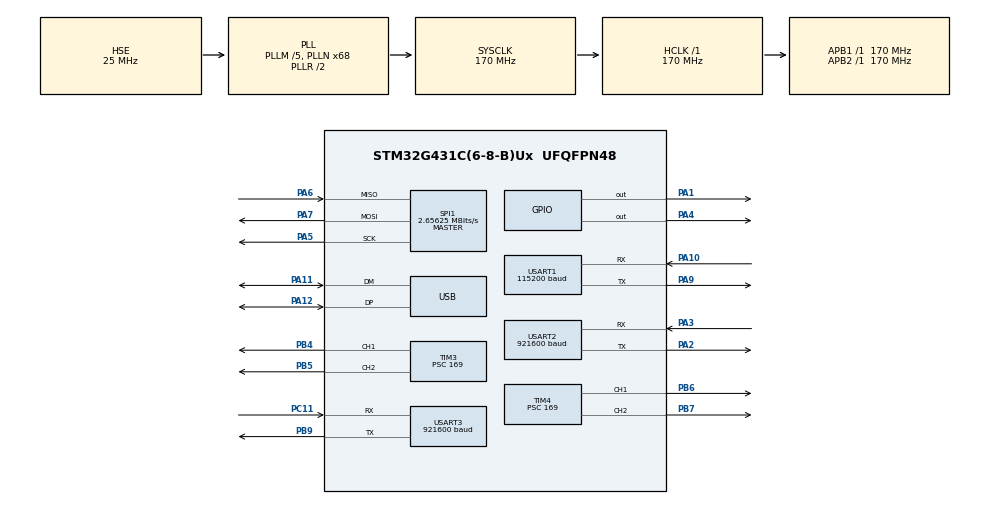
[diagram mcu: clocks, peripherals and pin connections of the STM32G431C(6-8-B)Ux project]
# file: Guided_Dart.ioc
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Dma.Request0=USART2_RX
Dma.Request1=USART2_TX
Dma.Request2=USART1_RX
Dma.Request3=USART1_TX
Dma.Request4=USART3_RX
Dma.Request5=USART3_TX
Dma.USART1_RX.2.Direction=DMA_PERIPH_TO_MEMORY
Dma.USART1_RX.2.EventEnable=DISABLE
Dma.USART1_RX.2.Instance=DMA1_Channel3
Dma.USART1_RX.2.MemDataAlignment=DMA_MDATAALIGN_BYTE
Dma.USART1_RX.2.MemInc=DMA_MINC_ENABLE
Dma.USART1_RX.2.Mode=DMA_NORMAL
Dma.USART1_RX.2.PeriphDataAlignment=DMA_PDATAALIGN_BYTE
Dma.USART1_RX.2.PeriphInc=DMA_PINC_DISABLE
Dma.USART1_RX.2.Polarity=HAL_DMAMUX_REQ_GEN_RISING
Dma.USART1_RX.2.Priority=DMA_PRIORITY_LOW
Dma.USART1_RX.2.RequestNumber=1
Dma.USART1_RX.2.SignalID=NONE
Dma.USART1_RX.2.SyncEnable=DISABLE
Dma.USART1_RX.2.SyncPolarity=HAL_DMAMUX_SYNC_NO_EVENT
Dma.USART1_RX.2.SyncRequestNumber=1
Dma.USART1_RX.2.SyncSignalID=NONE
Dma.USART1_TX.3.Direction=DMA_MEMORY_TO_PERIPH
Dma.USART1_TX.3.EventEnable=DISABLE
Dma.USART1_TX.3.Instance=DMA1_Channel4
Dma.USART1_TX.3.MemDataAlignment=DMA_MDATAALIGN_BYTE
Dma.USART1_TX.3.MemInc=DMA_MINC_ENABLE
Dma.USART1_TX.3.Mode=DMA_NORMAL
Dma.USART1_TX.3.PeriphDataAlignment=DMA_PDATAALIGN_BYTE
Dma.USART1_TX.3.PeriphInc=DMA_PINC_DISABLE
Dma.USART1_TX.3.Polarity=HAL_DMAMUX_REQ_GEN_RISING
Dma.USART1_TX.3.Priority=DMA_PRIORITY_LOW
Dma.USART1_TX.3.RequestNumber=1
Dma.USART1_TX.3.SignalID=NONE
Dma.USART1_TX.3.SyncEnable=DISABLE
Dma.USART1_TX.3.SyncPolarity=HAL_DMAMUX_SYNC_NO_EVENT
Dma.USART1_TX.3.SyncRequestNumber=1
Dma.USART1_TX.3.SyncSignalID=NONE
Dma.USART2_RX.0.Direction=DMA_PERIPH_TO_MEMORY
Dma.USART2_RX.0.EventEnable=DISABLE
Dma.USART2_RX.0.Instance=DMA1_Channel1
Dma.USART2_RX.0.MemDataAlignment=DMA_MDATAALIGN_BYTE
Dma.USART2_RX.0.MemInc=DMA_MINC_ENABLE
Dma.USART2_RX.0.Mode=DMA_NORMAL
Dma.USART2_RX.0.PeriphDataAlignment=DMA_PDATAALIGN_BYTE
Dma.USART2_RX.0.PeriphInc=DMA_PINC_DISABLE
Dma.USART2_RX.0.Polarity=HAL_DMAMUX_REQ_GEN_RISING
Dma.USART2_RX.0.Priority=DMA_PRIORITY_LOW
Dma.USART2_RX.0.RequestNumber=1
Dma.USART2_RX.0.SignalID=NONE
Dma.USART2_RX.0.SyncEnable=DISABLE
Dma.USART2_RX.0.SyncPolarity=HAL_DMAMUX_SYNC_NO_EVENT
Dma.USART2_RX.0.SyncRequestNumber=1
Dma.USART2_RX.0.SyncSignalID=NONE
Dma.USART2_TX.1.Direction=DMA_MEMORY_TO_PERIPH
Dma.USART2_TX.1.EventEnable=DISABLE
Dma.USART2_TX.1.Instance=DMA1_Channel2
Dma.USART2_TX.1.MemDataAlignment=DMA_MDATAALIGN_BYTE
Dma.USART2_TX.1.MemInc=DMA_MINC_ENABLE
Dma.USART2_TX.1.Mode=DMA_NORMAL
Dma.USART2_TX.1.PeriphDataAlignment=DMA_PDATAALIGN_BYTE
Dma.USART2_TX.1.PeriphInc=DMA_PINC_DISABLE
Dma.USART2_TX.1.Polarity=HAL_DMAMUX_REQ_GEN_RISING
Dma.USART2_TX.1.Priority=DMA_PRIORITY_LOW
Dma.USART2_TX.1.RequestNumber=1
Dma.USART2_TX.1.SignalID=NONE
Dma.USART2_TX.1.SyncEnable=DISABLE
Dma.USART2_TX.1.SyncPolarity=HAL_DMAMUX_SYNC_NO_EVENT
Dma.USART2_TX.1.SyncRequestNumber=1
Dma.USART2_TX.1.SyncSignalID=NONE
Dma.USART3_RX.4.Direction=DMA_PERIPH_TO_MEMORY
Dma.USART3_RX.4.EventEnable=DISABLE
Dma.USART3_RX.4.Instance=DMA1_Channel5
Dma.USART3_RX.4.MemDataAlignment=DMA_MDATAALIGN_BYTE
Dma.USART3_RX.4.MemInc=DMA_MINC_ENABLE
Dma.USART3_RX.4.Mode=DMA_NORMAL
Dma.USART3_RX.4.PeriphDataAlignment=DMA_PDATAALIGN_BYTE
Dma.USART3_RX.4.PeriphInc=DMA_PINC_DISABLE
Dma.USART3_RX.4.Polarity=HAL_DMAMUX_REQ_GEN_RISING
Dma.USART3_RX.4.Priority=DMA_PRIORITY_LOW
Dma.USART3_RX.4.RequestNumber=1
Dma.USART3_RX.4.SignalID=NONE
Dma.USART3_RX.4.SyncEnable=DISABLE
Dma.USART3_RX.4.SyncPolarity=HAL_DMAMUX_SYNC_NO_EVENT
Dma.USART3_RX.4.SyncRequestNumber=1
Dma.USART3_RX.4.SyncSignalID=NONE
Dma.USART3_TX.5.Direction=DMA_MEMORY_TO_PERIPH
Dma.USART3_TX.5.EventEnable=DISABLE
Dma.USART3_TX.5.Instance=DMA1_Channel6
Dma.USART3_TX.5.MemDataAlignment=DMA_MDATAALIGN_BYTE
Dma.USART3_TX.5.MemInc=DMA_MINC_ENABLE
Dma.USART3_TX.5.Mode=DMA_NORMAL
Dma.USART3_TX.5.PeriphDataAlignment=DMA_PDATAALIGN_BYTE
Dma.USART3_TX.5.PeriphInc=DMA_PINC_DISABLE
Dma.USART3_TX.5.Polarity=HAL_DMAMUX_REQ_GEN_RISING
Dma.USART3_TX.5.Priority=DMA_PRIORITY_LOW
Dma.USART3_TX.5.RequestNumber=1
Dma.USART3_TX.5.SignalID=NONE
Dma.USART3_TX.5.SyncEnable=DISABLE
Dma.USART3_TX.5.SyncPolarity=HAL_DMAMUX_SYNC_NO_EVENT
Dma.USART3_TX.5.SyncRequestNumber=1
Dma.USART3_TX.5.SyncSignalID=NONE
Mcu.Family=STM32G4
Mcu.Name=STM32G431C(6-8-B)Ux
Mcu.Package=UFQFPN48
NVIC.DMA1_Channel1_IRQn=true\:0\:0\:false\:false\:true\:false\:true\:true
NVIC.DMA1_Channel2_IRQn=true\:0\:0\:false\:false\:true\:false\:true\:true
NVIC.DMA1_Channel3_IRQn=true\:0\:0\:false\:false\:true\:false\:true\:true
NVIC.DMA1_Channel4_IRQn=true\:0\:0\:false\:false\:true\:false\:true\:true
NVIC.DMA1_Channel5_IRQn=true\:0\:0\:false\:false\:true\:false\:true\:true
NVIC.DMA1_Channel6_IRQn=true\:0\:0\:false\:false\:true\:false\:true\:true
NVIC.PriorityGroup=NVIC_PRIORITYGROUP_4
NVIC.TIM1_BRK_TIM15_IRQn=true\:0\:0\:false\:false\:true\:true\:true\:true
NVIC.TIM2_IRQn=true\:0\:0\:false\:false\:true\:true\:true\:true
NVIC.USART1_IRQn=true\:0\:0\:false\:false\:true\:true\:true\:true
NVIC.USART2_IRQn=true\:0\:0\:false\:false\:true\:true\:true\:true
NVIC.USART3_IRQn=true\:0\:0\:false\:false\:true\:true\:true\:true
NVIC.USB_LP_IRQn=true\:0\:0\:false\:false\:true\:false\:true\:true
PA1.GPIO_Speed=GPIO_SPEED_FREQ_HIGH
PA1.PinState=GPIO_PIN_SET
PA1.Signal=GPIO_Output
PA10.Mode=Asynchronous
PA10.Signal=USART1_RX
PA11.Mode=Device
PA11.Signal=USB_DM
PA12.Mode=Device
PA12.Signal=USB_DP
PA13.Mode=Serial_Wire
PA13.Signal=SYS_JTMS-SWDIO
PA14.Mode=Serial_Wire
PA14.Signal=SYS_JTCK-SWCLK
PA2.Mode=Asynchronous
PA2.Signal=USART2_TX
PA3.Mode=Asynchronous
PA3.Signal=USART2_RX
PA4.GPIO_PuPd=GPIO_PULLUP
PA4.GPIO_Speed=GPIO_SPEED_FREQ_HIGH
PA4.PinState=GPIO_PIN_SET
PA4.Signal=GPIO_Output
PA5.GPIO_PuPd=GPIO_PULLUP
PA5.GPIO_Speed=GPIO_SPEED_FREQ_VERY_HIGH
PA5.Mode=Full_Duplex_Master
PA5.Signal=SPI1_SCK
PA6.GPIO_PuPd=GPIO_PULLUP
PA6.GPIO_Speed=GPIO_SPEED_FREQ_VERY_HIGH
PA6.Mode=Full_Duplex_Master
PA6.Signal=SPI1_MISO
PA7.GPIO_PuPd=GPIO_PULLUP
PA7.GPIO_Speed=GPIO_SPEED_FREQ_VERY_HIGH
PA7.Mode=Full_Duplex_Master
PA7.Signal=SPI1_MOSI
PA9.Mode=Asynchronous
PA9.Signal=USART1_TX
PB4.Signal=S_TIM3_CH1
PB5.Signal=S_TIM3_CH2
PB6.Signal=S_TIM4_CH1
PB7.Signal=S_TIM4_CH2
PB9.Mode=Asynchronous
PB9.Signal=USART3_TX
PC11.Mode=Asynchronous
PC11.Signal=USART3_RX
PF0-OSC_IN.Mode=HSE-External-Oscillator
PF0-OSC_IN.Signal=RCC_OSC_IN
PF1-OSC_OUT.Mode=HSE-External-Oscillator
PF1-OSC_OUT.Signal=RCC_OSC_OUT
ProjectManager.HeapSize=0x200
ProjectManager.StackSize=0x400
ProjectManager.TargetToolchain=STM32CubeIDE
RCC.ADC12Freq_Value=170000000
RCC.AHBFreq_Value=170000000
RCC.APB1Freq_Value=170000000
RCC.APB1TimFreq_Value=170000000
RCC.APB2Freq_Value=170000000
RCC.APB2TimFreq_Value=170000000
RCC.CK48CLockSelection=RCC_USBCLKSOURCE_HSI48
RCC.CortexFreq_Value=170000000
RCC.EXTERNAL_CLOCK_VALUE=12288000
RCC.HCLKFreq_Value=170000000
RCC.HSE_VALUE=25000000
RCC.HSI48_VALUE=48000000
RCC.HSI_VALUE=16000000
RCC.LSE_VALUE=32768
RCC.PLLM=RCC_PLLM_DIV5
RCC.PLLN=68
RCC.PLLQ=RCC_PLLQ_DIV4
RCC.PLLSourceVirtual=RCC_PLLSOURCE_HSE
RCC.SYSCLKFreq_VALUE=170000000
RCC.SYSCLKSource=RCC_SYSCLKSOURCE_PLLCLK
RCC.USBFreq_Value=48000000
RCC.VCOOutputFreq_Value=340000000
SH.S_TIM3_CH1.0=TIM3_CH1,PWM Generation1 CH1
SH.S_TIM3_CH2.0=TIM3_CH2,PWM Generation2 CH2
SH.S_TIM4_CH1.0=TIM4_CH1,PWM Generation1 CH1
SH.S_TIM4_CH2.0=TIM4_CH2,PWM Generation2 CH2
SPI1.BaudRatePrescaler=SPI_BAUDRATEPRESCALER_64
SPI1.CLKPhase=SPI_PHASE_2EDGE
SPI1.CLKPolarity=SPI_POLARITY_HIGH
SPI1.CalculateBaudRate=2.65625 MBits/s
SPI1.DataSize=SPI_DATASIZE_8BIT
SPI1.Direction=SPI_DIRECTION_2LINES
SPI1.Mode=SPI_MODE_MASTER
SPI1.VirtualType=VM_MASTER
TIM15.PeriodNoDither=9999
TIM15.Prescaler=169
TIM2.PeriodNoDither=99
TIM2.Prescaler=169
TIM3.Channel-PWM\ Generation1\ CH1=TIM_CHANNEL_1
TIM3.Channel-PWM\ Generation2\ CH2=TIM_CHANNEL_2
TIM3.PeriodNoDither=4999
TIM3.Prescaler=169
TIM4.Channel-PWM\ Generation1\ CH1=TIM_CHANNEL_1
TIM4.Channel-PWM\ Generation2\ CH2=TIM_CHANNEL_2
TIM4.PeriodNoDither=4999
TIM4.Prescaler=169
USART1.BaudRate=115200
USART1.VirtualMode-Asynchronous=VM_ASYNC
USART2.BaudRate=921600
USART2.VirtualMode-Asynchronous=VM_ASYNC
USART3.BaudRate=921600
USART3.VirtualMode-Asynchronous=VM_ASYNC
USB_DEVICE.CLASS_NAME_FS=CDC
USB_DEVICE.VirtualMode=Cdc
USB_DEVICE.VirtualModeFS=Cdc_FS
VP_SYS_VS_DBSignals.Mode=DisableDeadBatterySignals
VP_TIM15_VS_ClockSourceINT.Mode=Internal
VP_TIM2_VS_ClockSourceINT.Mode=Internal
VP_TIM3_VS_ClockSourceINT.Mode=Internal
VP_TIM4_VS_ClockSourceINT.Mode=Internal
VP_USB_DEVICE_VS_USB_DEVICE_CDC_FS.Mode=CDC_FS
board=custom

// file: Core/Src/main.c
  /* USER CODE BEGIN Header */
/**
  ******************************************************************************
  * @file           : main.c
  * @brief          : Main program body
  ******************************************************************************
  * @attention
  *
  * Copyright (c) 2026 STMicroelectronics.
  * All rights reserved.
  *
  * This software is licensed under terms that can be found in the LICENSE file
  * in the root directory of this software component.
  * If no LICENSE file comes with this software, it is provided AS-IS.
  *
  ******************************************************************************
  */
/* USER CODE END Header */
#include "main.h"
#include "dma.h"
#include "spi.h"
#include "tim.h"
#include "usart.h"
#include "usb_device.h"
#include "gpio.h"

/* USER CODE BEGIN Includes */
#include "component.h"
/* USER CODE END Includes */

void SystemClock_Config(void);

int main(void)
{

  /* MCU Configuration--------------------------------------------------------*/

  /* Reset of all peripherals, Initializes the Flash interface and the Systick. */
  HAL_Init();

  /* Configure the system clock */
  SystemClock_Config();

  /* USER CODE BEGIN SysInit */

  /* 重配 SysTick: HAL_Init() 时 HCLK=16MHz, 现在已是 170MHz, 必须更新 */
  HAL_InitTick(0);   /* priority=0, 和 TIM2 同级 */

  /* USER CODE END SysInit */

  /* Initialize all configured peripherals */
  MX_GPIO_Init();
  MX_DMA_Init();
  MX_SPI1_Init();
  MX_TIM3_Init();
  MX_USB_Device_Init();
  MX_USART1_UART_Init();
  MX_USART2_UART_Init();
  MX_TIM2_Init();
  MX_TIM4_Init();
  MX_TIM15_Init();
  MX_USART3_UART_Init();
  /* USER CODE BEGIN 2 */
  dart_control_init();   /* 内部已调用 vision_link_init() */
  /* USER CODE END 2 */

  /* Infinite loop */
  while (1)
  {

    /* USER CODE BEGIN 3 */
    dart_control_process();
  }
  /* USER CODE END 3 */
}

void SystemClock_Config(void)
{
  RCC_OscInitTypeDef RCC_OscInitStruct = {0};
  RCC_ClkInitTypeDef RCC_ClkInitStruct = {0};

  /** Configure the main internal regulator output voltage
  */
  HAL_PWREx_ControlVoltageScaling(PWR_REGULATOR_VOLTAGE_SCALE1_BOOST);

  /** Initializes the RCC Oscillators according to the specified parameters
  * in the RCC_OscInitTypeDef structure.
  */
  RCC_OscInitStruct.OscillatorType = RCC_OSCILLATORTYPE_HSI48|RCC_OSCILLATORTYPE_HSE;
  RCC_OscInitStruct.HSEState = RCC_HSE_ON;
  RCC_OscInitStruct.HSI48State = RCC_HSI48_ON;
  RCC_OscInitStruct.PLL.PLLState = RCC_PLL_ON;
  RCC_OscInitStruct.PLL.PLLSource = RCC_PLLSOURCE_HSE;
  RCC_OscInitStruct.PLL.PLLM = RCC_PLLM_DIV5;
  RCC_OscInitStruct.PLL.PLLN = 68;
  RCC_OscInitStruct.PLL.PLLP = RCC_PLLP_DIV2;
  RCC_OscInitStruct.PLL.PLLQ = RCC_PLLQ_DIV4;
  RCC_OscInitStruct.PLL.PLLR = RCC_PLLR_DIV2;
  if (HAL_RCC_OscConfig(&RCC_OscInitStruct) != HAL_OK)
  {
    Error_Handler();
  }

  /** Initializes the CPU, AHB and APB buses clocks
  */
  RCC_ClkInitStruct.ClockType = RCC_CLOCKTYPE_HCLK|RCC_CLOCKTYPE_SYSCLK
                              |RCC_CLOCKTYPE_PCLK1|RCC_CLOCKTYPE_PCLK2;
  RCC_ClkInitStruct.SYSCLKSource = RCC_SYSCLKSOURCE_PLLCLK;
  RCC_ClkInitStruct.AHBCLKDivider = RCC_SYSCLK_DIV1;
  RCC_ClkInitStruct.APB1CLKDivider = RCC_HCLK_DIV1;
  RCC_ClkInitStruct.APB2CLKDivider = RCC_HCLK_DIV1;

  if (HAL_RCC_ClockConfig(&RCC_ClkInitStruct, FLASH_LATENCY_4) != HAL_OK)
  {
    Error_Handler();
  }
}

/* USER CODE BEGIN 4 */

void HAL_TIM_PeriodElapsedCallback(TIM_HandleTypeDef *htim)
{
    if (htim->Instance == TIM2) {
        dart_control_timer_isr();
    }
}

/* USER CODE END 4 */

void Error_Handler(void)
{
  __disable_irq();
  while (1)
  {
  }
}
